# RTC register map
Vendor: Texas Instruments
Peripheral module from a debugger description file (folder am335x).
Registers are 32-bit, access per field, no defined reset value unless marked. A register's access mark holds for its fields unless they carry their own. Offsets are as the file gives them; lines under a group give offsets from that group; [hi:lo] are bit positions; {n}, {i} and the like mark numbered series; 'fields as' and 'values as' point back to an identical list; <NAME> marks a mode.

## RTC
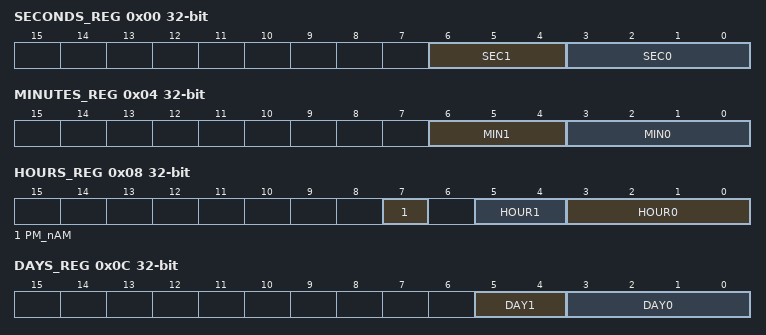
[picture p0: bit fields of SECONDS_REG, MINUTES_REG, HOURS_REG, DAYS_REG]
0x00 SECONDS_REG — The SECONDS_REG is used to program the required seconds value of the current time. Seconds are stored as BCD format. In BCD format, the decimal numbers 0 through 9 are encoded with their binary equivalent. If the seconds value is 45, then the value of SEC0 is 5 and value of SEC1 is 4.
  [6:4] SEC1 rw — 2nd digit of seconds, Range is 0 to 5
  [3:0] SEC0 rw — 1st digit of seconds, Range is 0 to 9
0x04 MINUTES_REG — The MINUTES_REG is used to program the minutes value of the current time. Minutes are stored as BCD format. In BCD format, the decimal numbers 0 through 9 are encoded with their binary equivalent. If the minutes value is 32, then the value of MIN0 is 2 and value of MIN1 is 3.
  [6:4] MIN1 rw — 2nd digit of minutes, Range is 0 to 5
  [3:0] MIN0 rw — 1st digit of minutes, Range is 0 to 9
0x08 HOURS_REG — The HOURS_REG is used to program the hours value of the current time. Hours are stored as BCD format. In BCD format, the decimal numbers 0 through 9 are encoded with their binary equivalent. In 24Hr time mode if you want to set the hour as 18, then HOUR0 is set as 8 and HOUR1 is set as 1.
  [7] PM_nAM rw — Only used in PM_AM mode (otherwise 0)
  [5:4] HOUR1 rw — 2nd digit of hours, Range is 0 to 2
  [3:0] HOUR0 rw — 1st digit of hours, Range is 0 to 9
0x0C DAYS_REG — The DAYS_REG is used to program the day of the month value of the current date. Days are stored as BCD format. In BCD format, the decimal numbers 0 through 9 are encoded with their binary equivalent. If the day value of the date is 28, DAY0 is set as 8 and DAY1 is set as 2.
  [5:4] DAY1 rw — 2nd digit of days, Range is 0 to 3
  [3:0] DAY0 rw — 1st digit of days, Range is 0 to 9
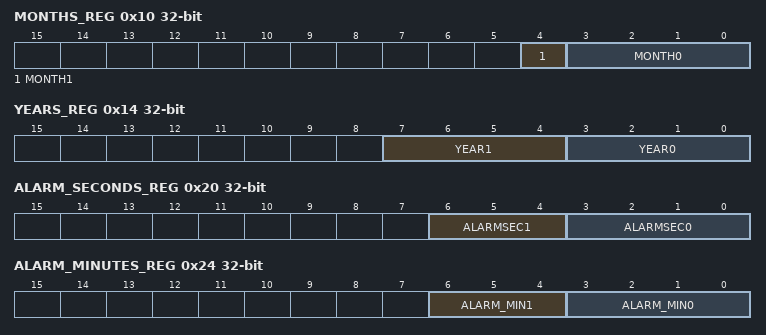
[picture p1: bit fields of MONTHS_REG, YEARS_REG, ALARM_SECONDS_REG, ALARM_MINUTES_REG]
0x10 MONTHS_REG — The MONTHS_REG is used to set the month in the year value of the current date. Months are stored as BCD format. In BCD format, the decimal numbers 0 through 9 are encoded with their binary equivalent. Usual notation is taken for month value: 1 = January, 2 = February, continuing until 12 = December.
  [4] MONTH1 rw — 2nd digit of months, Range is 0 to 1
  [3:0] MONTH0 rw — 1st digit of months, Range is 0 to 9
0x14 YEARS_REG — The YEARS_REG is used to program the year value of the current date. The year value is represented by only the last 2 digits and is stored as BCD format. In BCD format, the decimal numbers 0 through 9 are encoded with their binary equivalent. The year 1979 is programmed as 79 with YEAR0 set as 9 and YEAR1 set as 7.
  [7:4] YEAR1 rw — 2nd digit of years, Range is 0 to 9
  [3:0] YEAR0 rw — 1st digit of years, Range is 0 to 9
0x18 WEEKS_REG — The WEEKS_REG is used to program the day of the week value of the current date. The day of the week is stored as BCD format. In BCD format, the decimal numbers 0 through 9 are encoded with their binary equivalent. Sunday is treated as 0, Monday 1, and ending at Saturday with 6.
  [2:0] WEEK rw — 1st digit of days in a week, Range from 0 (Sunday) to 6 (Saturday)
0x20 ALARM_SECONDS_REG — The ALARM_SECONDS_REG is used to program the second value for the alarm interrupt. Seconds are stored as BCD format. In BCD format, the decimal numbers 0 through 9 are encoded with their binary equivalent.
  [6:4] ALARMSEC1 rw — 2nd digit of seconds, Range is 0 to 5
  [3:0] ALARMSEC0 rw — 1st digit of seconds, Range is 0 to 9
0x24 ALARM_MINUTES_REG — The ALARM_MINUTES_REG is used to program the minute value for the alarm interrupt. Minutes are stored as BCD format. In BCD format, the decimal numbers 0 through 9 are encoded with their binary equivalent.
  [6:4] ALARM_MIN1 rw — 2nd digit of minutes, Range is 0 to 5
  [3:0] ALARM_MIN0 rw — 1st digit of minutes, Range is 0 to 9
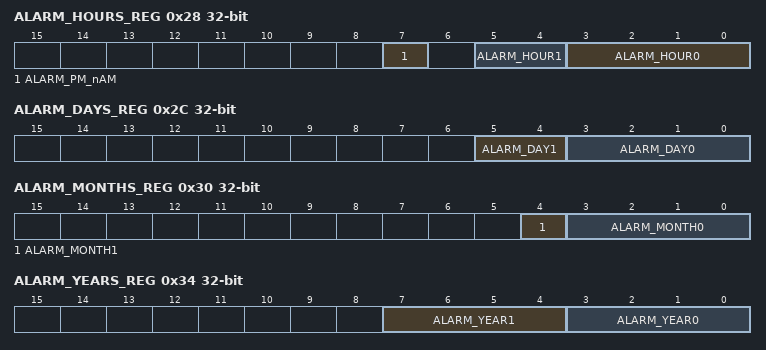
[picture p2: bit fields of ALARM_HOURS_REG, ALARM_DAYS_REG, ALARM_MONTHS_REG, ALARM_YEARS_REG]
0x28 ALARM_HOURS_REG — The ALARM_HOURS_REG is used to program the hour value for the alarm interrupt. Hours are stored as BCD format. In BCD format, the decimal numbers 0 through 9 are encoded with their binary equivalent.
  [7] ALARM_PM_nAM rw — Only used in PM_AM mode (otherwise 0)
  [5:4] ALARM_HOUR1 rw — 2nd digit of hours, Range is 0 to 2
  [3:0] ALARM_HOUR0 rw — 1st digit of hours, Range is 0 to 9
0x2C ALARM_DAYS_REG — The ALARM_DAYS_REG is used to program the day of the month value for the alarm interrupt. Days are stored as BCD format. In BCD format, the decimal numbers 0 through 9 are encoded with their binary equivalent.
  [5:4] ALARM_DAY1 rw — 2nd digit for days, Range from 0 to 3
  [3:0] ALARM_DAY0 rw — 1st digit for days, Range from 0 to 9
0x30 ALARM_MONTHS_REG — The ALARM_MONTHS_REG is used to program the month in the year value for the alarm interrupt. The month is stored as BCD format. In BCD format, the decimal numbers 0 through 9 are encoded with their binary equivalent.
  [4] ALARM_MONTH1 rw — 2nd digit of months, Range from 0 to 1
  [3:0] ALARM_MONTH0 rw — 1st digit of months, Range from 0 to 9
0x34 ALARM_YEARS_REG — The ALARM_YEARS_REG is used to program the year for the alarm interrupt. Only the last two digits are used to represent the year and is stored as BCD format. In BCD format, the decimal numbers 0 through 9 are encoded with their binary equivalent.
  [7:4] ALARM_YEAR1 rw — 2nd digit of years, Range from 0 to 9
  [3:0] ALARM_YEAR0 rw — 1st digit of years, Range from 0 to 9
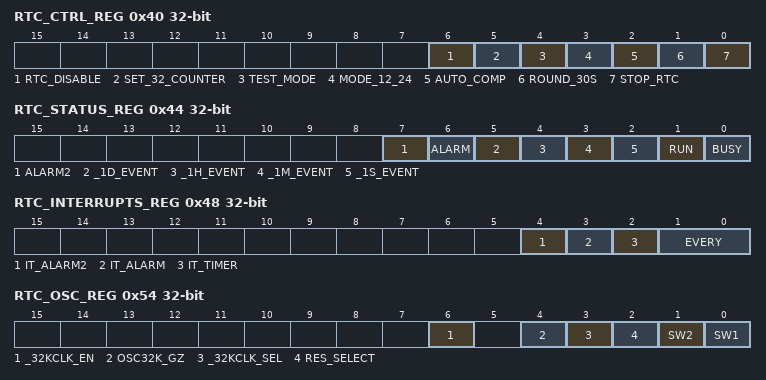
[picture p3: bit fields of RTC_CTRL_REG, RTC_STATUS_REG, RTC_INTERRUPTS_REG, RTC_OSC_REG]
0x40 RTC_CTRL_REG — The RTC_CTRL_REG contains the controls to enable/disable the RTC, set the 12/24 hour time mode, to enable the 30 second rounding feature, and to STOP/START the RTC. The SET_32_COUNTER bit must only be used when the RTC is frozen. The RTC_DISABLE bit must only be used to completely disable the RTC function. When this bit is set, the 32 kHz clock is gated and the RTC is frozen. From this point, resetting this bit to zero can lead to unexpected behavior. This bit should only be used if the RTC function is unwanted in the application, in order to save power. MODE_12_24: It is possible to switch between the two modes at any time without disturbing the RTC. Read or write is always performed with the current mode. Auto compensation is enabled by the AUTO_COMP bit. If the COMP_REG value is positive, compensation occurs after the second change event. COMP_REG cycles are removed from the next second. If the COMP_REG value is negative, compensation occurs before the second change event. COMP_REG cycles are added to the current second. This enables it to compensate with one 32-kHz period accuracy each hour. The ROUND_30S bit is a toggle bit; the ARM can only write 1 and the RTC clears it. If the ARM sets the ROUND_30S bit and then reads it, the ARM reads 1 until the round-to-the-closest-minute is performed at the next second. The ARM can stop the RTC by clearing the STOP_RTC bit (owing to internal resynchronization, the RUN bit of the status register (STATUS_REG) must be checked to ensure that the RTC is frozen), then update TC values, and re-start the RTC by resetting the STOP_RTC bit.
  [6] RTC_DISABLE rw — Disable RTC module and gate 32-kHz reference clock.
  [5] SET_32_COUNTER rw — Set the 32-kHz counter with the value stored in the compensation registers when the SET_32_COUNTER bit is set.
  [4] TEST_MODE rw
  [3] MODE_12_24 rw — Enable 12-hour mode for HOURS and ALARMHOURS registers.
  [2] AUTO_COMP rw — Enable oscillator compensation mode.
  [1] ROUND_30S rw — Enable one-time rounding to nearest minute on next time register read.
  [0] STOP_RTC rw — Stop the RTC 32-kHz counter.
0x44 RTC_STATUS_REG — The RTC_STATUS_REG contains bits that signal the status of interrupts, events to the processor. Status for the alarm interrupt and timer events are notified by the register. The alarm interrupt keeps its low level until the ARM writes 1 in the ALARM bit of the RTC_STATUS_REG register. ALARM2: This bit will indicate the status of the alarm interrupt. Writing a 1 to the bit clears the interrupt. ALARM: This bit will indicate the status of the alarm interrupt. Writing a 1 to the bit clears the interrupt. 1D_EVENT1: This bit will indicate if a day event has occurred. An interrupt will be generated to the processor based on the masking of the interrupt controller. 1H_EVENT1: This bit will indicate if an hour event has occurred. An interrupt will be generated to the processor based on the masking of the interrupt controller. 1M_EVENT1: This bit will indicate if a minute event has occurred. An interrupt will be generated to the processor based on the masking of the interrupt controller. 1S_EVENT1: This bit will indicate if a second event has occurred. An interrupt will be generated to the processor based on the masking of the interrupt controller. RUN: This bit will indicate if RTC is frozen or it is running. The RUN bit shows the real state of the RTC. Indeed, because the STOP_RTC signal is resynchronized on 32-kHz clock the action of this bit is delayed. BUSY: This bit will give the status of RTC module. The Time and alarm registers can be modified only when this bit is 0. The timer interrupt is a negative edge sensitive low-level pulse (1 OCP cycle duration).
  [7] ALARM2 rw — Indicates that an alarm2 interrupt has been generated. Software needs to wait 31 s before it clears this status to allow pmic_pwr_enable 1 ' 0 transmission.
  [6] ALARM rw — Indicates that an alarm interrupt has been generated
  [5] _1D_EVENT ro — One day has occurred
  [4] _1H_EVENT ro — One hour has occurred
  [3] _1M_EVENT ro — One minute has occurred
  [2] _1S_EVENT ro — One second has occurred
  [1] RUN ro — RTC is frozen or is running.
  [0] BUSY ro — Status of RTC module.
0x48 RTC_INTERRUPTS_REG — The RTC_INTERRUPTS_REG is used to enable or disable the RTC from generating interrupts. The timer interrupt and alarm interrupt can be controlled using this register. The ARM must respect the BUSY period to prevent spurious interrupt. To set a period timer interrupt, the respective period value must be set in the EVERY field. For example, to set a periodic timer interrupt for every hour, the EVERY field has to be set to 2. Along with this the IT_TIMER bit also has to be set for the periodic interrupt to be generated. IT_ALARM bit has to be set to generate an alarm interrupt.
  [4] IT_ALARM2 rw — Enable one interrupt when the alarm value is reached (TC ALARM2 registers) by the TC registers
  [3] IT_ALARM rw — Enable one interrupt when the alarm value is reached (TC ALARM registers) by the TC registers
  [2] IT_TIMER rw — Enable periodic interrupt.
  [1:0] EVERY rw — Interrupt period.
0x4C RTC_COMP_LSB_REG — The COMP_LSB_REG is used to program the LSB value of the 32 kHz periods to be added to the 32 kHz counter every hour. This is used to compensate the oscillator drift. The COMP_LSB_REG works together with the compensation (MSB) register (COMP_MSB_REG). The AUTOCOMP bit in the control register (CTRL_REG) must be enabled for compensation to take place. This register must be written in two's complement. That means that to add one 32-kHz oscillator period every hour, the ARM must write FFFFh into RTC_COMP_MSB_REG and RTC_COMP_LSB_REG. To remove one 32-kHz oscillator period every hour, the ARM must write 0001h into RTC_COMP_MSB_REG and RTC_COMP_LSB_REG. The 7FFFh value is forbidden.
  [7:0] RTC_COMP_LSB rw — Indicates number of 32-kHz periods to be added into the 32-kHz counter every hour
0x50 RTC_COMP_MSB_REG — The COMP_MSB_REG is used to program the MSB value of the 32 kHz periods to be added to the 32 kHz counter every hour. This is used to compensate the oscillator drift. The COMP_MSB_REG works together with the compensation (LSB) register (COMP_LSB_REG) to set the hourly oscillator compensation value. The AUTOCOMP bit in the control register (CTRL_REG) must be enabled for compensation to take place. This register must be written in two's complement. That means that to add one 32-kHz oscillator period every hour, the ARM must write FFFFh into RTC_COMP_MSB_REG and RTC_COMP_LSB_REG. To remove one 32-kHz oscillator period every hour, the ARM must write 0001h into RTC_COMP_MSB_REG and RTC_COMP_LSB_REG. The 7FFFh value is forbidden.
  [7:0] RTC_COMP_MSB rw — Indicates number of 32-kHz periods to be added into the 32-kHz counter every hour
0x54 RTC_OSC_REG
  [6] _32KCLK_EN rw — 32-kHz clock enable post clock mux of rtc_32k_clk_rtc_32k_aux_clk and rtc_32k_clk_rtc_32k_clk
  [4] OSC32K_GZ rw — Disable the oscillator and apply high impedance to the output
  [3] _32KCLK_SEL rw — 32-kHz clock source select
  [2] RES_SELECT rw — External feedback resistor
  [1] SW2 rw — Inverter size adjustment
  [0] SW1 rw — Inverter size adjustment
{0x60+4i} RTC_SCRATCH{i}_REG rw (i=0..2) — The RTC_SCRATCH{i}_REG is used to hold some required values for the RTC register.
  [31:0] RTCSCRATCH{i} — Scratch registers, available to program
0x6C KICK0R wo — The kick registers (KICKnR) are used to enable and disable write protection on the RTC registers. Out of reset, the RTC registers are write-protected. To disable write protection, correct keys must be written to the KICKnR registers. The Kick0 register allows writing to unlock the kick0 data. To disable RTC register write protection, the value of 83E7 0B13h must be written to KICK0R, followed by the value of 95A4 F1E0h written to KICK1R. RTC register write protection is enabled when any value is written to KICK0R.
  [31:0] KICK0 — Kick0 data
0x70 KICK1R wo — The kick registers (KICKnR) are used to enable and disable write protection on the RTC registers. Out of reset, the RTC registers are write-protected. To disable write protection, correct keys must be written to the KICKnR registers. The Kick1 register allows writing to unlock the kick1 data and the kicker mechanism to write to other MMRs. To disable RTC register write protection, the value of 83E7 0B13h must be written to KICK0R, followed by the value of 95A4 F1E0h written to KICK1R.
  [31:0] KICK1 — Kick1 data
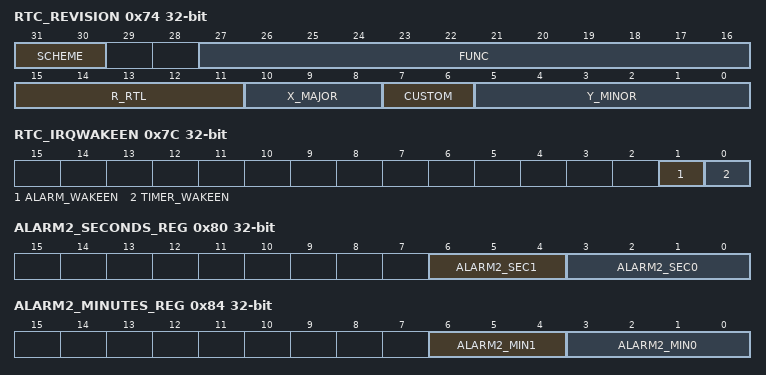
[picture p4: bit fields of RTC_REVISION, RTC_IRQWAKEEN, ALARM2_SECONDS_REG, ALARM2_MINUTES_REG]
0x74 RTC_REVISION ro
  [31:30] SCHEME — Used to distinguish between old scheme and current
  [27:16] FUNC — Function indicates a software compatible module family
  [15:11] R_RTL — RTL Version (R)
  [10:8] X_MAJOR — Major Revision
  [7:6] CUSTOM — Indicates a special version for a particular device
  [5:0] Y_MINOR — Minor Revision (Y)
0x78 RTC_SYSCONFIG
  [1:0] IDLEMODE rw — Configuration of the local target state management mode, By definition target can handle read/write transaction as long as it is out of IDLE state.
0x7C RTC_IRQWAKEEN
  [1] ALARM_WAKEEN rw — Wakeup generation for event Alarm.
  [0] TIMER_WAKEEN rw — Wakeup generation for event Timer.
0x80 ALARM2_SECONDS_REG — The ALARM2_SECONDS_REG is used to program the second value for the alarm2 time. Seconds are stored as BCD format. In BCD format, the decimal numbers 0 through 9 are encoded with their binary equivalent.
  [6:4] ALARM2_SEC1 rw — 2nd digit of seconds, Range is 0 to 5
  [3:0] ALARM2_SEC0 rw — 1st digit of seconds, Range is 0 to 9
0x84 ALARM2_MINUTES_REG — The ALARM2_MINUTES_REG is used to program the minute value for the alarm2 time. Minutes are stored as BCD format. In BCD format, the decimal numbers 0 through 9 are encoded with their binary equivalent.
  [6:4] ALARM2_MIN1 rw — 2nd digit of minutes, Range is 0 to 5
  [3:0] ALARM2_MIN0 rw — 1st digit of minutes, Range is 0 to 9
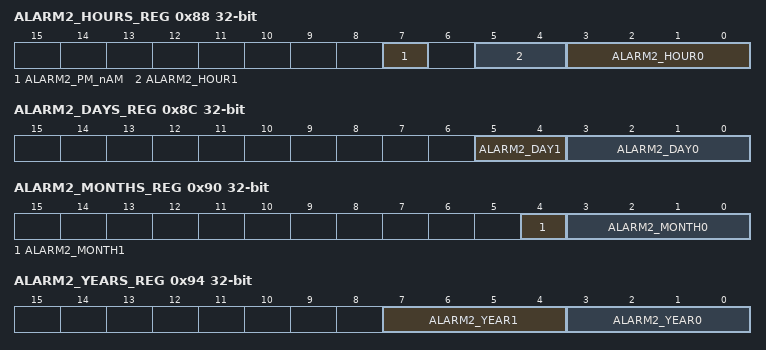
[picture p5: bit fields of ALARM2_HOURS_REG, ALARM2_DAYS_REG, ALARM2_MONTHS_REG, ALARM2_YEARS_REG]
0x88 ALARM2_HOURS_REG — The ALARM2_HOURS_REG is used to program the hour value for the alarm2 time. Hours are stored as BCD format. In BCD format, the decimal numbers 0 through 9 are encoded with their binary equivalent.
  [7] ALARM2_PM_nAM rw — Only used in PM_AM mode (otherwise 0)
  [5:4] ALARM2_HOUR1 rw — 2nd digit of hours, Range is 0 to 2
  [3:0] ALARM2_HOUR0 rw — 1st digit of hours, Range is 0 to 9
0x8C ALARM2_DAYS_REG — The ALARM2_DAYS_REG is used to program the day of the month value for the alarm2 date. Days are stored as BCD format. In BCD format, the decimal numbers 0 through 9 are encoded with their binary equivalent.
  [5:4] ALARM2_DAY1 rw — 2nd digit for days, Range from 0 to 3
  [3:0] ALARM2_DAY0 rw — 1st digit for days, Range from 0 to 9
0x90 ALARM2_MONTHS_REG — The ALARM2_MONTHS_REG is used to program the month in the year value for the alarm2 date. The month is stored as BCD format. In BCD format, the decimal numbers 0 through 9 are encoded with their binary equivalent.
  [4] ALARM2_MONTH1 rw — 2nd digit of months, Range from 0 to 1
  [3:0] ALARM2_MONTH0 rw — 1st digit of months, Range from 0 to 9
0x94 ALARM2_YEARS_REG — The ALARM2_YEARS_REG is used to program the year for the alarm2 date. Only the last two digits are used to represent the year and stored as BCD format. In BCD format, the decimal numbers 0 through 9 are encoded with their binary equivalent.
  [7:4] ALARM2_YEAR1 rw — 2nd digit of years, Range from 0 to 9
  [3:0] ALARM2_YEAR0 rw — 1st digit of years, Range from 0 to 9
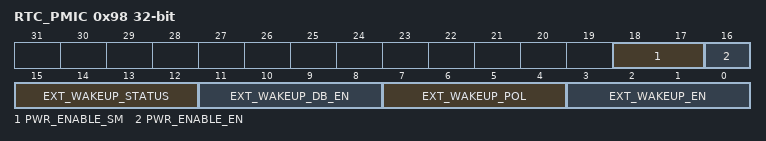
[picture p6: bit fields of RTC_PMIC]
0x98 RTC_PMIC
  [18:17] PWR_ENABLE_SM ro — Power state machine state.
  [16] PWR_ENABLE_EN rw — Enable for PMIC_POWER_EN signal
  [15:12] EXT_WAKEUP_STATUS rw — External wakeup status. Write 1 to clear EXT_WAKEUP_STATUS[n] status of ext_wakeup[n].
  [11:8] EXT_WAKEUP_DB_EN rw — External wakeup debounce enabled. EXT_WAKEUP_DB_EN[n] controls ext_wakeup[n]
  [7:4] EXT_WAKEUP_POL rw — External wakeup inputs polarity. EXT_WAKEUP_POL[n] controls ext_wakeup[n].
  [3:0] EXT_WAKEUP_EN rw — Enable external wakeup inputs. EXT_WAKEUP_EN[n] controls ext_wakeup[n].
0x9C RTC_DEBOUNCE — The debounce timer uses the 32768-Hz clock. It allows choosing the timing or the accuracy of debouncing . A register receives a bit from the reference pin. You will choose the timing if you use the debouncing like a timer, or you will choose the accuracy if you use the debouncing like a real debouncing. The debouncing will be finished when the reference pin will stay the same value (defined in DEBOUNCE_REG) for a defined time.
  [7:0] DEBOUNCE_REG rw — Debounce time. A value, n, other than 0 results in a debounce time of 30.52 s*(n+1).
